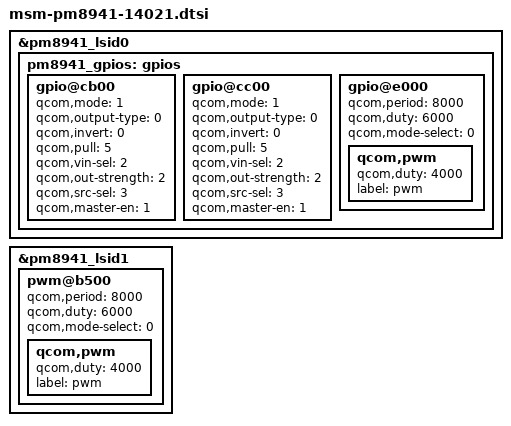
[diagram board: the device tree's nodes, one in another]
/* Copyright (c) 2012-2014, The Linux Foundation. All rights reserved.
 *
 * This program is free software; you can redistribute it and/or modify
 * it under the terms of the GNU General Public License version 2 and
 * only version 2 as published by the Free Software Foundation.
 *
 * This program is distributed in the hope that it will be useful,
 * but WITHOUT ANY WARRANTY; without even the implied warranty of
 * MERCHANTABILITY or FITNESS FOR A PARTICULAR PURPOSE.  See the
 * GNU General Public License for more details.
 */

&pm8941_lsid0 {
	pm8941_gpios: gpios {
		gpio@cb00 {
			qcom,mode = <1>;	 /* QPNP_PIN_MODE_DIG_OUT */
			qcom,output-type = <0>;	 /* QPNP_PIN_OUT_BUF_CMOS */
			qcom,invert = <0>;	 /* QPNP_PIN_INVERT_DISABLE */
			qcom,pull = <5>;	 /* QPNP_PIN_PULL_NO */
			qcom,vin-sel = <2>;	 /* QPNP_PIN_VIN2, VREG_S3A */
			qcom,out-strength = <2>; /* QPNP_PIN_OUT_STRENGTH_MED */
			qcom,src-sel = <3>;	 /* QPNP_PIN_SEL_FUNC_2 */
			qcom,master-en = <1>;	 /* Enable GPIO by default */
		};

		gpio@cc00 {
			qcom,mode = <1>;	 /* QPNP_PIN_MODE_DIG_OUT */
			qcom,output-type = <0>;	 /* QPNP_PIN_OUT_BUF_CMOS */
			qcom,invert = <0>;	 /* QPNP_PIN_INVERT_DISABLE */
			qcom,pull = <5>;	 /* QPNP_PIN_PULL_NO */
			qcom,vin-sel = <2>;	 /* QPNP_PIN_VIN2, VREG_S3A */
			qcom,out-strength = <2>; /* QPNP_PIN_OUT_STRENGTH_MED */
			qcom,src-sel = <3>;	 /* QPNP_PIN_SEL_FUNC_2 */
			qcom,master-en = <1>;	 /* Enable GPIO by default */
		};

		gpio@e000 {
			qcom,period = <8000>;
			qcom,duty = <6000>;
			qcom,mode-select = <0>; /* Enable PWM signal by default */
			status = "okay";
			qcom,pwm {
				qcom,duty = <4000>;
				label = "pwm";
			};
		};
	};
};

&pm8941_lsid1 {
	pwm@b500 {
		qcom,period = <8000>;
		qcom,duty = <6000>;
		qcom,mode-select = <0>;	/* Enable PWM signal by default */
		status = "okay";
		qcom,pwm {
			qcom,duty = <4000>;
			label = "pwm";
		};
	};
};
